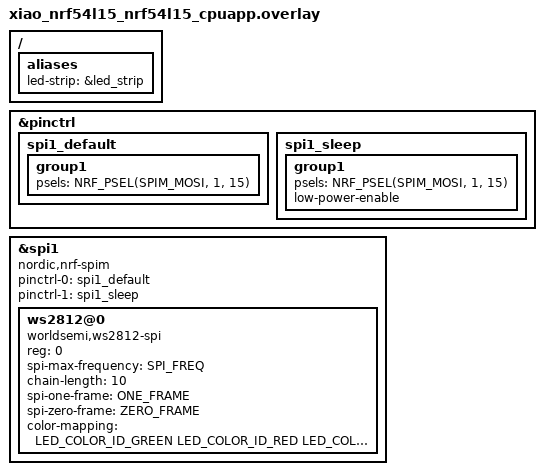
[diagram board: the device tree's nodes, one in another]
/*
 * Device tree overlay for XIAO nRF54L15
 * LED strip configuration
 */

#include <zephyr/dt-bindings/led/led.h>

&pinctrl {
	spi1_default: spi1_default {
		group1 {
			psels = <NRF_PSEL(SPIM_MOSI, 1, 15)>;
		};
	};

	spi1_sleep: spi1_sleep {
		group1 {
			psels = <NRF_PSEL(SPIM_MOSI, 1, 15)>;
			low-power-enable;
		};
	};
};

&spi1 {
	compatible = "nordic,nrf-spim";
	status = "okay";
	pinctrl-0 = <&spi1_default>;
	pinctrl-1 = <&spi1_sleep>;
	pinctrl-names = "default", "sleep";
	led-strip: ws2812@0 {
		compatible = "worldsemi,ws2812-spi";
		reg = <0>;
		spi-max-frequency = <SPI_FREQ>;
		chain-length = <10>;
		spi-one-frame = <ONE_FRAME>;
		spi-zero-frame = <ZERO_FRAME>;
		color-mapping = <LED_COLOR_ID_GREEN
				 LED_COLOR_ID_RED
				 LED_COLOR_ID_BLUE>;
	};
};

/ {
	aliases {
		led-strip = &led_strip;
	};
};
